# test register map
Vendor: Test Ltd.; Series: TestSeries; File version: 1.1
Test svd file
CPU: CM3 r1p2, little endian, MPU, FPU, double-precision FPU, I-cache, D-cache, 4 interrupt priority bits, 9 interrupts
Address unit: 32 bits
Registers are 32-bit, read-write, reset 0x0 unless marked. A register's access mark holds for its fields unless they carry their own. Offsets are from the block's base; lines under a group give offsets from that group; [hi:lo] are bit positions; {n}, {i} and the like mark numbered series; 'fields as' and 'values as' point back to an identical list; <NAME> marks a mode.

## Memory map
0x40002000 TestPeripheral1 size 0x400 — Test peripheral number 1

## Interrupts
1 TEST0 (TestPeripheral1) — Test interrupt 0
2 TEST1 (TestPeripheral1) — Test interrupt 1

## TestPeripheral1 — Test peripheral number 1
Base 0x40002000; register names take the prefix prefix; register names take the suffix suffix
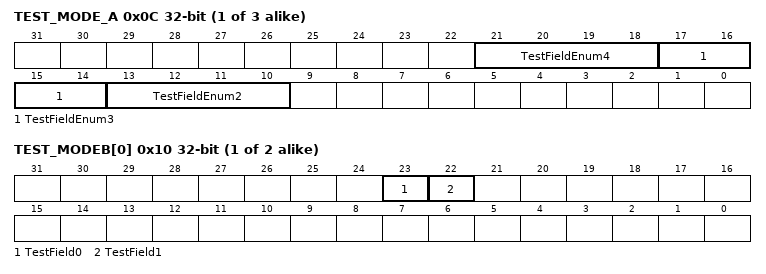
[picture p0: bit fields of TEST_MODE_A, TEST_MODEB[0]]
0x0C TEST_MODE_{x} (x=A,B,C; step 0x4) read-clears — Test register MODEA
  [4n+5:4n+2] TestFieldEnum{n} (n=2..4) — Test field enumerated value 0
    0=Disable device; 1=Enable device
{0x10+8i} TEST_MODEB[{i}] (i=0..1) read-clears — Test register MODEB
  [23] TestField0 write-as-read, [22] TestField1

## Licence text in the file
MIT License
